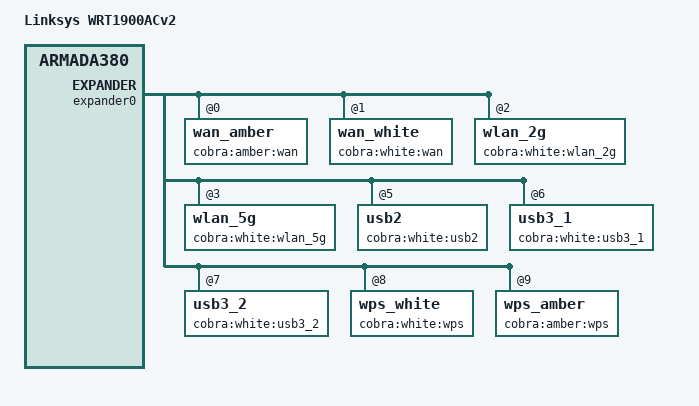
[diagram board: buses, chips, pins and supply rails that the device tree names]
// SPDX-License-Identifier: (GPL-2.0 OR MIT)
/*
 * Device Tree file for the Linksys WRT1900ACv2 (Cobra)
 *
 * Copyright (C) 2015 Imre Kaloz <kaloz@openwrt.org>
 */

/dts-v1/;
#include "armada-385-linksys.dtsi"

/ {
	model = "Linksys WRT1900ACv2";
	compatible = "linksys,wrt1900ac-v2", "linksys,cobra",
		     "linksys,armada385", "marvell,armada385",
		     "marvell,armada380";
};

&expander0 {
	wan_amber@0 {
		label = "cobra:amber:wan";
		reg = <0x0>;
	};

	wan_white@1 {
		label = "cobra:white:wan";
		reg = <0x1>;
	};

	wlan_2g@2 {
		label = "cobra:white:wlan_2g";
		reg = <0x2>;
	};

	wlan_5g@3 {
		label = "cobra:white:wlan_5g";
		reg = <0x3>;
	};

	usb2@5 {
		label = "cobra:white:usb2";
		reg = <0x5>;
	};

	usb3_1@6 {
		label = "cobra:white:usb3_1";
		reg = <0x6>;
	};

	usb3_2@7 {
		label = "cobra:white:usb3_2";
		reg = <0x7>;
	};

	wps_white@8 {
		label = "cobra:white:wps";
		reg = <0x8>;
	};

	wps_amber@9 {
		label = "cobra:amber:wps";
		reg = <0x9>;
	};
};

&gpio_leds {
	power {
		label = "cobra:white:power";
	};

	sata {
		label = "cobra:white:sata";
	};
};

&nand {
	/* 128MiB */
	partitions {
		compatible = "fixed-partitions";
		#address-cells = <1>;
		#size-cells = <1>;

				partition@0 {
					label = "u-boot";
					reg = <0x0000000 0x200000>;  /* 2MB */
					read-only;
				};

				partition@100000 {
					label = "u_env";
					reg = <0x200000 0x40000>;    /* 256KB */
				};

				partition@140000 {
					label = "s_env";
					reg = <0x240000 0x40000>;    /* 256KB */
				};

				partition@900000 {
					label = "devinfo";
					reg = <0x900000 0x100000>;   /* 1MB */
					read-only;
				};

				/* kernel1 overlaps with rootfs1 by design */
				partition@a00000 {
					label = "linux";
					reg = <0xa00000 0x2800000>;  /* 40MB */
				};

				partition@e00000 {
					label = "rootfs";
					reg = <0xe00000 0x2400000>;    /* 37MB */
				};

				/* kernel2 overlaps with rootfs2 by design */
				partition@3200000 {
					label = "linux2";
					reg = <0x3200000 0x2700000>; /* 40MB */
				};

				partition@3600000 {
					label = "rootfs2";
					reg = <0x3600000 0x2300000>; /* 34MB */
				};

				partition@5900000 {
					label = "nvram";
					reg = <0x5900000 0x40000>;
				};

				/*
				 * 38MB, last MB is for the BBT, not writable
				 */
				partition@5a00000 {
					label = "ddwrt";
					reg = <0x5a00000 0x2500000>;
				};


				/*
				 * Unused area between "s_env" and "devinfo".
				 * Moved here because otherwise the renumbered
				 * partitions would break the bootloader
				 * supplied bootargs
				 */
				partition@180000 {
					label = "unused_area";
					reg = <0x280000 0x680000>;   /* 6.5MB */
				};
	};
};

&pcie1 {
	mwlwifi {
		marvell,chainmask = <4 4>;
		marvell,powertable {
			AU =
				<36 0 0xd 0xd 0xd 0xd 0xd 0xd 0xd 0xd 0xe 0xe 0xe 0xe 0xe 0xe 0xe 0xe 0 0xf>,
				<40 0 0xd 0xd 0xd 0xd 0xd 0xd 0xd 0xd 0xe 0xe 0xe 0xe 0xe 0xe 0xe 0xe 0 0xf>,
				<44 0 0xd 0xd 0xd 0xd 0xd 0xd 0xd 0xd 0xe 0xe 0xe 0xe 0xe 0xe 0xe 0xe 0 0xf>,
				<48 0 0xd 0xd 0xd 0xd 0xd 0xd 0xd 0xd 0xe 0xe 0xe 0xe 0xe 0xe 0xe 0xe 0 0xf>,
				<52 0 0xd 0xd 0xd 0xd 0xd 0xd 0xd 0xd 0xe 0xe 0xe 0xe 0xe 0xe 0xe 0xe 0 0xf>,
				<56 0 0xd 0xd 0xd 0xd 0xd 0xd 0xd 0xd 0xe 0xe 0xe 0xe 0xe 0xe 0xe 0xe 0 0xf>,
				<60 0 0xd 0xd 0xd 0xd 0xd 0xd 0xd 0xd 0xe 0xe 0xe 0xe 0xe 0xe 0xe 0xe 0 0xf>,
				<64 0 0xd 0xd 0xd 0xd 0xd 0xd 0xd 0xd 0xe 0xe 0xe 0xe 0xe 0xe 0xe 0xe 0 0xf>,
				<100 0 0x14 0x14 0x14 0x14 0x14 0x14 0x14 0x14 0x14 0x14 0x14 0x14 0x14 0x14 0x14 0x14 0 0xf>,
				<104 0 0x14 0x14 0x14 0x14 0x14 0x14 0x14 0x14 0x14 0x14 0x14 0x14 0x14 0x14 0x14 0x14 0 0xf>,
				<108 0 0x14 0x14 0x14 0x14 0x14 0x14 0x14 0x14 0x14 0x14 0x14 0x14 0x14 0x14 0x14 0x14 0 0xf>,
				<112 0 0x14 0x14 0x14 0x14 0x14 0x14 0x14 0x14 0x14 0x14 0x14 0x14 0x14 0x14 0x14 0x14 0 0xf>,
				<116 0 0x14 0x14 0x14 0x14 0x14 0x14 0x14 0x14 0x14 0x14 0x14 0x14 0x14 0x14 0x14 0x14 0 0xf>,
				<120 0 0x14 0x14 0x14 0x14 0x14 0x14 0x14 0x14 0x14 0x14 0x14 0x14 0x14 0x14 0x14 0x14 0 0xf>,
				<124 0 0x14 0x14 0x14 0x14 0x14 0x14 0x14 0x14 0x14 0x14 0x14 0x14 0x14 0x14 0x14 0x14 0 0xf>,
				<128 0 0x14 0x14 0x14 0x14 0x14 0x14 0x14 0x14 0x14 0x14 0x14 0x14 0x14 0x14 0x14 0x14 0 0xf>,
				<132 0 0x14 0x14 0x14 0x14 0x14 0x14 0x14 0x14 0x14 0x14 0x14 0x14 0x14 0x14 0x14 0x14 0 0xf>,
				<136 0 0x14 0x14 0x14 0x14 0x14 0x14 0x14 0x14 0x14 0x14 0x14 0x14 0x14 0x14 0x14 0x14 0 0xf>,
				<140 0 0x14 0x14 0x14 0x14 0x14 0x14 0x14 0x14 0x14 0x14 0x14 0x14 0x14 0x14 0x14 0x14 0 0xf>,
				<149 0 0x19 0x19 0x19 0x17 0x19 0x19 0x16 0x15 0x19 0x19 0x16 0x15 0x19 0x19 0x16 0x15 0 0xf>,
				<153 0 0x19 0x19 0x19 0x17 0x19 0x19 0x16 0x15 0x19 0x19 0x16 0x15 0x19 0x19 0x16 0x15 0 0xf>,
				<157 0 0x19 0x19 0x19 0x17 0x19 0x19 0x16 0x15 0x19 0x19 0x16 0x15 0x19 0x19 0x16 0x15 0 0xf>,
				<161 0 0x19 0x19 0x19 0x17 0x19 0x19 0x16 0x15 0x19 0x19 0x16 0x15 0x19 0x19 0x16 0x15 0 0xf>,
				<165 0 0x19 0x19 0x19 0x17 0x19 0x19 0x16 0x15 0x19 0x19 0x16 0x15 0x19 0x19 0x16 0x15 0 0xf>;
			CA =
				<36 0 0x9 0x9 0x9 0x9 0x9 0x9 0x9 0x9 0x9 0x9 0x9 0x9 0x9 0x9 0x9 0x9 0 0xf>,
				<40 0 0x9 0x9 0x9 0x9 0x9 0x9 0x9 0x9 0x9 0x9 0x9 0x9 0x9 0x9 0x9 0x9 0 0xf>,
				<44 0 0x9 0x9 0x9 0x9 0x9 0x9 0x9 0x9 0x9 0x9 0x9 0x9 0x9 0x9 0x9 0x9 0 0xf>,
				<48 0 0x9 0x9 0x9 0x9 0x9 0x9 0x9 0x9 0x9 0x9 0x9 0x9 0x9 0x9 0x9 0x9 0 0xf>,
				<52 0 0x11 0x11 0x11 0x11 0x10 0x10 0x10 0x10 0x12 0x12 0x12 0x12 0x10 0x10 0x10 0x10 0 0xf>,
				<56 0 0x11 0x11 0x11 0x11 0x10 0x10 0x10 0x10 0x12 0x12 0x12 0x12 0x10 0x10 0x10 0x10 0 0xf>,
				<60 0 0x11 0x11 0x11 0x11 0x10 0x10 0x10 0x10 0x12 0x12 0x12 0x12 0x10 0x10 0x10 0x10 0 0xf>,
				<64 0 0x11 0x11 0x11 0x11 0x10 0x10 0x10 0x10 0x12 0x12 0x12 0x12 0x10 0x10 0x10 0x10 0 0xf>,
				<100 0 0x10 0x10 0x10 0x10 0x11 0x11 0x11 0x11 0x12 0x12 0x12 0x12 0x10 0x10 0x10 0x10 0 0xf>,
				<104 0 0x11 0x11 0x11 0x11 0x10 0x10 0x10 0x10 0x12 0x12 0x12 0x12 0x10 0x10 0x10 0x10 0 0xf>,
				<108 0 0x11 0x11 0x11 0x11 0x10 0x10 0x10 0x10 0x11 0x11 0x11 0x11 0x10 0x10 0x10 0x10 0 0xf>,
				<112 0 0x11 0x11 0x11 0x11 0x10 0x10 0x10 0x10 0x11 0x11 0x11 0x11 0x10 0x10 0x10 0x10 0 0xf>,
				<116 0 0x11 0x11 0x11 0x11 0x10 0x10 0x10 0x10 0x11 0x11 0x11 0x11 0x10 0x10 0x10 0x10 0 0xf>,
				<120 0 0x11 0x11 0x11 0x11 0x10 0x10 0x10 0x10 0x11 0x11 0x11 0x11 0x10 0x10 0x10 0x10 0 0xf>,
				<124 0 0x11 0x11 0x11 0x11 0x10 0x10 0x10 0x10 0x11 0x11 0x11 0x11 0x10 0x10 0x10 0x10 0 0xf>,
				<128 0 0x11 0x11 0x11 0x11 0x10 0x10 0x10 0x10 0x11 0x11 0x11 0x11 0x10 0x10 0x10 0x10 0 0xf>,
				<132 0 0x11 0x11 0x11 0x11 0x10 0x10 0x10 0x10 0x11 0x11 0x11 0x11 0x10 0x10 0x10 0x10 0 0xf>,
				<136 0 0x11 0x11 0x11 0x11 0x10 0x10 0x10 0x10 0x11 0x11 0x11 0x11 0x10 0x10 0x10 0x10 0 0xf>,
				<140 0 0x11 0x11 0x11 0x11 0x10 0x10 0x10 0x10 0x11 0x11 0x11 0x11 0x10 0x10 0x10 0x10 0 0xf>,
				<149 0 0x16 0x16 0x16 0x16 0x16 0x16 0x16 0x16 0x15 0x15 0x15 0x15 0x15 0x15 0x15 0x15 0 0xf>,
				<153 0 0x16 0x16 0x16 0x16 0x15 0x15 0x15 0x15 0x15 0x15 0x15 0x15 0x15 0x15 0x15 0x15 0 0xf>,
				<157 0 0x16 0x16 0x16 0x16 0x15 0x15 0x15 0x15 0x15 0x15 0x15 0x15 0x15 0x15 0x15 0x15 0 0xf>,
				<161 0 0x16 0x16 0x16 0x16 0x15 0x15 0x15 0x15 0x15 0x15 0x15 0x15 0x15 0x15 0x15 0x15 0 0xf>,
				<165 0 0x15 0x15 0x15 0x15 0x15 0x15 0x15 0x15 0x15 0x15 0x15 0x15 0x15 0x15 0x15 0x15 0 0xf>;
			CN =
				<36 0 0xd 0xd 0xd 0xd 0xd 0xd 0xd 0xd 0xe 0xe 0xe 0xe 0xe 0xe 0xe 0xe 0 0xf>,
				<40 0 0xd 0xd 0xd 0xd 0xd 0xd 0xd 0xd 0xe 0xe 0xe 0xe 0xe 0xe 0xe 0xe 0 0xf>,
				<44 0 0xd 0xd 0xd 0xd 0xd 0xd 0xd 0xd 0xe 0xe 0xe 0xe 0xe 0xe 0xe 0xe 0 0xf>,
				<48 0 0xd 0xd 0xd 0xd 0xd 0xd 0xd 0xd 0xe 0xe 0xe 0xe 0xe 0xe 0xe 0xe 0 0xf>,
				<52 0 0xd 0xd 0xd 0xd 0xd 0xd 0xd 0xd 0xe 0xe 0xe 0xe 0xe 0xe 0xe 0xe 0 0xf>,
				<56 0 0xd 0xd 0xd 0xd 0xd 0xd 0xd 0xd 0xe 0xe 0xe 0xe 0xe 0xe 0xe 0xe 0 0xf>,
				<60 0 0xd 0xd 0xd 0xd 0xd 0xd 0xd 0xd 0xe 0xe 0xe 0xe 0xe 0xe 0xe 0xe 0 0xf>,
				<64 0 0xd 0xd 0xd 0xd 0xd 0xd 0xd 0xd 0xe 0xe 0xe 0xe 0xe 0xe 0xe 0xe 0 0xf>,
				<100 0 0xd 0xd 0xd 0xd 0xd 0xd 0xd 0xd 0xe 0xe 0xe 0xe 0xe 0xe 0xe 0xe 0 0xf>,
				<104 0 0xd 0xd 0xd 0xd 0xd 0xd 0xd 0xd 0xe 0xe 0xe 0xe 0xe 0xe 0xe 0xe 0 0xf>,
				<108 0 0xd 0xd 0xd 0xd 0xd 0xd 0xd 0xd 0xe 0xe 0xe 0xe 0xe 0xe 0xe 0xe 0 0xf>,
				<112 0 0xd 0xd 0xd 0xd 0xd 0xd 0xd 0xd 0xe 0xe 0xe 0xe 0xe 0xe 0xe 0xe 0 0xf>,
				<116 0 0xd 0xd 0xd 0xd 0xd 0xd 0xd 0xd 0xe 0xe 0xe 0xe 0xe 0xe 0xe 0xe 0 0xf>,
				<120 0 0xd 0xd 0xd 0xd 0xd 0xd 0xd 0xd 0xe 0xe 0xe 0xe 0xe 0xe 0xe 0xe 0 0xf>,
				<124 0 0xd 0xd 0xd 0xd 0xd 0xd 0xd 0xd 0xe 0xe 0xe 0xe 0xe 0xe 0xe 0xe 0 0xf>,
				<128 0 0xd 0xd 0xd 0xd 0xd 0xd 0xd 0xd 0xe 0xe 0xe 0xe 0xe 0xe 0xe 0xe 0 0xf>,
				<132 0 0xd 0xd 0xd 0xd 0xd 0xd 0xd 0xd 0xe 0xe 0xe 0xe 0xe 0xe 0xe 0xe 0 0xf>,
				<136 0 0xd 0xd 0xd 0xd 0xd 0xd 0xd 0xd 0xe 0xe 0xe 0xe 0xe 0xe 0xe 0xe 0 0xf>,
				<140 0 0xd 0xd 0xd 0xd 0xd 0xd 0xd 0xd 0xe 0xe 0xe 0xe 0xe 0xe 0xe 0xe 0 0xf>,
				<149 0 0x14 0x14 0x14 0x14 0x13 0x13 0x13 0x13 0x11 0x11 0x11 0x11 0x10 0x10 0x10 0x10 0 0xf>,
				<153 0 0x16 0x16 0x16 0x16 0x15 0x15 0x15 0x15 0x14 0x14 0x14 0x14 0x10 0x10 0x10 0x10 0 0xf>,
				<157 0 0x16 0x16 0x16 0x16 0x15 0x15 0x15 0x15 0x14 0x14 0x14 0x14 0x10 0x10 0x10 0x10 0 0xf>,
				<161 0 0x16 0x16 0x16 0x16 0x15 0x15 0x15 0x15 0x14 0x14 0x14 0x14 0x10 0x10 0x10 0x10 0 0xf>,
				<165 0 0x13 0x13 0x13 0x13 0x13 0x13 0x13 0x13 0x14 0x14 0x14 0x14 0x10 0x10 0x10 0x10 0 0xf>;
			ETSI =
				<36 0 0xd 0xd 0xd 0xd 0xd 0xd 0xd 0xd 0xe 0xe 0xe 0xe 0xe 0xe 0xe 0xe 0 0xf>,
				<40 0 0xd 0xd 0xd 0xd 0xd 0xd 0xd 0xd 0xe 0xe 0xe 0xe 0xe 0xe 0xe 0xe 0 0xf>,
				<44 0 0xd 0xd 0xd 0xd 0xd 0xd 0xd 0xd 0xe 0xe 0xe 0xe 0xe 0xe 0xe 0xe 0 0xf>,
				<48 0 0xd 0xd 0xd 0xd 0xd 0xd 0xd 0xd 0xe 0xe 0xe 0xe 0xe 0xe 0xe 0xe 0 0xf>,
				<52 0 0xd 0xd 0xd 0xd 0xd 0xd 0xd 0xd 0xe 0xe 0xe 0xe 0xe 0xe 0xe 0xe 0 0xf>,
				<56 0 0xd 0xd 0xd 0xd 0xd 0xd 0xd 0xd 0xe 0xe 0xe 0xe 0xe 0xe 0xe 0xe 0 0xf>,
				<60 0 0xd 0xd 0xd 0xd 0xd 0xd 0xd 0xd 0xe 0xe 0xe 0xe 0xe 0xe 0xe 0xe 0 0xf>,
				<64 0 0xd 0xd 0xd 0xd 0xd 0xd 0xd 0xd 0xe 0xe 0xe 0xe 0xe 0xe 0xe 0xe 0 0xf>,
				<100 0 0xd 0xd 0xd 0xd 0xd 0xd 0xd 0xd 0xe 0xe 0xe 0xe 0xe 0xe 0xe 0xe 0 0xf>,
				<104 0 0xd 0xd 0xd 0xd 0xd 0xd 0xd 0xd 0xe 0xe 0xe 0xe 0xe 0xe 0xe 0xe 0 0xf>,
				<108 0 0xd 0xd 0xd 0xd 0xd 0xd 0xd 0xd 0xe 0xe 0xe 0xe 0xe 0xe 0xe 0xe 0 0xf>,
				<112 0 0xd 0xd 0xd 0xd 0xd 0xd 0xd 0xd 0xe 0xe 0xe 0xe 0xe 0xe 0xe 0xe 0 0xf>,
				<116 0 0xd 0xd 0xd 0xd 0xd 0xd 0xd 0xd 0xe 0xe 0xe 0xe 0xe 0xe 0xe 0xe 0 0xf>,
				<120 0 0xd 0xd 0xd 0xd 0xd 0xd 0xd 0xd 0xe 0xe 0xe 0xe 0xe 0xe 0xe 0xe 0 0xf>,
				<124 0 0xd 0xd 0xd 0xd 0xd 0xd 0xd 0xd 0xe 0xe 0xe 0xe 0xe 0xe 0xe 0xe 0 0xf>,
				<128 0 0xd 0xd 0xd 0xd 0xd 0xd 0xd 0xd 0xe 0xe 0xe 0xe 0xe 0xe 0xe 0xe 0 0xf>,
				<132 0 0xd 0xd 0xd 0xd 0xd 0xd 0xd 0xd 0xe 0xe 0xe 0xe 0xe 0xe 0xe 0xe 0 0xf>,
				<136 0 0xd 0xd 0xd 0xd 0xd 0xd 0xd 0xd 0xe 0xe 0xe 0xe 0xe 0xe 0xe 0xe 0 0xf>,
				<140 0 0xd 0xd 0xd 0xd 0xd 0xd 0xd 0xd 0xe 0xe 0xe 0xe 0xe 0xe 0xe 0xe 0 0xf>,
				<149 0 0xd 0xd 0xd 0xd 0xd 0xd 0xd 0xd 0xe 0xe 0xe 0xe 0xe 0xe 0xe 0xe 0 0xf>;
			FCC =
				<36 0 0x12 0x12 0x12 0x12 0x12 0x12 0x12 0x12 0x10 0x10 0x10 0x10 0xf 0xf 0xf 0xf 0 0xf>,
				<40 0 0x16 0x16 0x16 0x16 0x16 0x16 0x16 0x16 0x16 0x16 0x16 0x16 0xf 0xf 0xf 0xf 0 0xf>,
				<44 0 0x16 0x16 0x16 0x16 0x16 0x16 0x16 0x16 0x16 0x16 0x16 0x16 0xf 0xf 0xf 0xf 0 0xf>,
				<48 0 0x16 0x16 0x16 0x16 0x16 0x16 0x16 0x16 0x16 0x16 0x16 0x16 0xf 0xf 0xf 0xf 0 0xf>,
				<52 0 0x11 0x11 0x11 0x11 0x10 0x10 0x10 0x10 0x12 0x12 0x12 0x12 0x10 0x10 0x10 0x10 0 0xf>,
				<56 0 0x11 0x11 0x11 0x11 0x10 0x10 0x10 0x10 0x12 0x12 0x12 0x12 0x10 0x10 0x10 0x10 0 0xf>,
				<60 0 0x11 0x11 0x11 0x11 0x10 0x10 0x10 0x10 0x12 0x12 0x12 0x12 0x10 0x10 0x10 0x10 0 0xf>,
				<64 0 0x11 0x11 0x11 0x11 0x10 0x10 0x10 0x10 0x12 0x12 0x12 0x12 0x10 0x10 0x10 0x10 0 0xf>,
				<100 0 0x10 0x10 0x10 0x10 0x11 0x11 0x11 0x11 0x12 0x12 0x12 0x12 0x10 0x10 0x10 0x10 0 0xf>,
				<104 0 0x11 0x11 0x11 0x11 0x10 0x10 0x10 0x10 0x12 0x12 0x12 0x12 0x10 0x10 0x10 0x10 0 0xf>,
				<108 0 0x11 0x11 0x11 0x11 0x10 0x10 0x10 0x10 0x11 0x11 0x11 0x11 0x10 0x10 0x10 0x10 0 0xf>,
				<112 0 0x11 0x11 0x11 0x11 0x10 0x10 0x10 0x10 0x11 0x11 0x11 0x11 0x10 0x10 0x10 0x10 0 0xf>,
				<116 0 0x11 0x11 0x11 0x11 0x10 0x10 0x10 0x10 0x11 0x11 0x11 0x11 0x10 0x10 0x10 0x10 0 0xf>,
				<120 0 0x11 0x11 0x11 0x11 0x10 0x10 0x10 0x10 0x11 0x11 0x11 0x11 0x10 0x10 0x10 0x10 0 0xf>,
				<124 0 0x11 0x11 0x11 0x11 0x10 0x10 0x10 0x10 0x11 0x11 0x11 0x11 0x10 0x10 0x10 0x10 0 0xf>,
				<128 0 0x11 0x11 0x11 0x11 0x10 0x10 0x10 0x10 0x11 0x11 0x11 0x11 0x10 0x10 0x10 0x10 0 0xf>,
				<132 0 0x11 0x11 0x11 0x11 0x10 0x10 0x10 0x10 0x11 0x11 0x11 0x11 0x10 0x10 0x10 0x10 0 0xf>,
				<136 0 0x11 0x11 0x11 0x11 0x10 0x10 0x10 0x10 0x11 0x11 0x11 0x11 0x10 0x10 0x10 0x10 0 0xf>,
				<140 0 0x11 0x11 0x11 0x11 0x10 0x10 0x10 0x10 0x11 0x11 0x11 0x11 0x10 0x10 0x10 0x10 0 0xf>,
				<149 0 0x16 0x16 0x16 0x16 0x16 0x16 0x16 0x16 0x15 0x15 0x15 0x15 0x15 0x15 0x15 0x15 0 0xf>,
				<153 0 0x16 0x16 0x16 0x16 0x15 0x15 0x15 0x15 0x15 0x15 0x15 0x15 0x15 0x15 0x15 0x15 0 0xf>,
				<157 0 0x16 0x16 0x16 0x16 0x15 0x15 0x15 0x15 0x15 0x15 0x15 0x15 0x15 0x15 0x15 0x15 0 0xf>,
				<161 0 0x16 0x16 0x16 0x16 0x15 0x15 0x15 0x15 0x15 0x15 0x15 0x15 0x15 0x15 0x15 0x15 0 0xf>,
				<165 0 0x15 0x15 0x15 0x15 0x15 0x15 0x15 0x15 0x15 0x15 0x15 0x15 0x15 0x15 0x15 0x15 0 0xf>;
		};
	};
};

&pcie2 {
	mwlwifi {
		marvell,chainmask = <4 4>;
		marvell,powertable {
			AU =
				<1 0 0xa 0xa 0xa 0xa 0xa 0xa 0xa 0xa 0xa 0xa 0xa 0xa 0x0 0x0 0x0 0x0 0 0xf>,
				<2 0 0xa 0xa 0xa 0xa 0xa 0xa 0xa 0xa 0xa 0xa 0xa 0xa 0x0 0x0 0x0 0x0 0 0xf>,
				<3 0 0xa 0xa 0xa 0xa 0xa 0xa 0xa 0xa 0xa 0xa 0xa 0xa 0x0 0x0 0x0 0x0 0 0xf>,
				<4 0 0xa 0xa 0xa 0xa 0xa 0xa 0xa 0xa 0xa 0xa 0xa 0xa 0x0 0x0 0x0 0x0 0 0xf>,
				<5 0 0xa 0xa 0xa 0xa 0xa 0xa 0xa 0xa 0xa 0xa 0xa 0xa 0x0 0x0 0x0 0x0 0 0xf>,
				<6 0 0xa 0xa 0xa 0xa 0xa 0xa 0xa 0xa 0xa 0xa 0xa 0xa 0x0 0x0 0x0 0x0 0 0xf>,
				<7 0 0xa 0xa 0xa 0xa 0xa 0xa 0xa 0xa 0xa 0xa 0xa 0xa 0x0 0x0 0x0 0x0 0 0xf>,
				<8 0 0xa 0xa 0xa 0xa 0xa 0xa 0xa 0xa 0xa 0xa 0xa 0xa 0x0 0x0 0x0 0x0 0 0xf>,
				<9 0 0xa 0xa 0xa 0xa 0xa 0xa 0xa 0xa 0xa 0xa 0xa 0xa 0x0 0x0 0x0 0x0 0 0xf>,
				<10 0 0xa 0xa 0xa 0xa 0xa 0xa 0xa 0xa 0xa 0xa 0xa 0xa 0x0 0x0 0x0 0x0 0 0xf>,
				<11 0 0xa 0xa 0xa 0xa 0xa 0xa 0xa 0xa 0xa 0xa 0xa 0xa 0x0 0x0 0x0 0x0 0 0xf>;
			CA =
				<1 0 0x17 0x10 0x10 0x10 0xf 0xf 0xf 0xf 0xe 0xe 0xe 0xe 0x0 0x0 0x0 0x0 0 0xf>,
				<2 0 0x18 0x16 0x16 0x16 0x16 0x16 0x16 0x14 0x11 0x11 0x11 0x11 0x0 0x0 0x0 0x0 0 0xf>,
				<3 0 0x18 0x16 0x16 0x16 0x16 0x16 0x16 0x14 0x11 0x11 0x11 0x11 0x0 0x0 0x0 0x0 0 0xf>,
				<4 0 0x18 0x16 0x16 0x16 0x16 0x16 0x16 0x14 0x11 0x11 0x11 0x11 0x0 0x0 0x0 0x0 0 0xf>,
				<5 0 0x18 0x16 0x16 0x16 0x16 0x16 0x16 0x14 0x11 0x11 0x11 0x11 0x0 0x0 0x0 0x0 0 0xf>,
				<6 0 0x18 0x16 0x16 0x16 0x16 0x16 0x16 0x14 0x11 0x11 0x11 0x11 0x0 0x0 0x0 0x0 0 0xf>,
				<7 0 0x18 0x16 0x16 0x16 0x16 0x16 0x16 0x14 0x11 0x11 0x11 0x11 0x0 0x0 0x0 0x0 0 0xf>,
				<8 0 0x18 0x16 0x16 0x16 0x16 0x16 0x16 0x14 0x11 0x11 0x11 0x11 0x0 0x0 0x0 0x0 0 0xf>,
				<9 0 0x18 0x16 0x16 0x16 0x16 0x16 0x16 0x14 0x11 0x11 0x11 0x11 0x0 0x0 0x0 0x0 0 0xf>,
				<10 0 0x18 0x16 0x16 0x16 0x16 0x16 0x16 0x14 0x11 0x11 0x11 0x11 0x0 0x0 0x0 0x0 0 0xf>,
				<11 0 0x17 0x12 0x12 0x12 0x13 0x13 0x13 0x13 0xf 0xf 0xf 0xf 0x0 0x0 0x0 0x0 0 0xf>;
			CN =
				<1 0 0xa 0xa 0xa 0xa 0xa 0xa 0xa 0xa 0xa 0xa 0xa 0xa 0x0 0x0 0x0 0x0 0 0xf>,
				<2 0 0xa 0xa 0xa 0xa 0xa 0xa 0xa 0xa 0xa 0xa 0xa 0xa 0x0 0x0 0x0 0x0 0 0xf>,
				<3 0 0xa 0xa 0xa 0xa 0xa 0xa 0xa 0xa 0xa 0xa 0xa 0xa 0x0 0x0 0x0 0x0 0 0xf>,
				<4 0 0xa 0xa 0xa 0xa 0xa 0xa 0xa 0xa 0xa 0xa 0xa 0xa 0x0 0x0 0x0 0x0 0 0xf>,
				<5 0 0xa 0xa 0xa 0xa 0xa 0xa 0xa 0xa 0xa 0xa 0xa 0xa 0x0 0x0 0x0 0x0 0 0xf>,
				<6 0 0xa 0xa 0xa 0xa 0xa 0xa 0xa 0xa 0xa 0xa 0xa 0xa 0x0 0x0 0x0 0x0 0 0xf>,
				<7 0 0xa 0xa 0xa 0xa 0xa 0xa 0xa 0xa 0xa 0xa 0xa 0xa 0x0 0x0 0x0 0x0 0 0xf>,
				<8 0 0xa 0xa 0xa 0xa 0xa 0xa 0xa 0xa 0xa 0xa 0xa 0xa 0x0 0x0 0x0 0x0 0 0xf>,
				<9 0 0xa 0xa 0xa 0xa 0xa 0xa 0xa 0xa 0xa 0xa 0xa 0xa 0x0 0x0 0x0 0x0 0 0xf>,
				<10 0 0xa 0xa 0xa 0xa 0xa 0xa 0xa 0xa 0xa 0xa 0xa 0xa 0x0 0x0 0x0 0x0 0 0xf>,
				<11 0 0xa 0xa 0xa 0xa 0xa 0xa 0xa 0xa 0xa 0xa 0xa 0xa 0x0 0x0 0x0 0x0 0 0xf>,
				<12 0 0xa 0xa 0xa 0xa 0xa 0xa 0xa 0xa 0xa 0xa 0xa 0xa 0x0 0x0 0x0 0x0 0 0xf>,
				<13 0 0xa 0xa 0xa 0xa 0xa 0xa 0xa 0xa 0xa 0xa 0xa 0xa 0x0 0x0 0x0 0x0 0 0xf>,
				<14 0 0xa 0xa 0xa 0xa 0xa 0xa 0xa 0xa 0xa 0xa 0xa 0xa 0x0 0x0 0x0 0x0 0 0xf>;
			ETSI =
				<1 0 0xa 0xa 0xa 0xa 0xa 0xa 0xa 0xa 0xa 0xa 0xa 0xa 0x0 0x0 0x0 0x0 0 0xf>,
				<2 0 0xa 0xa 0xa 0xa 0xa 0xa 0xa 0xa 0xa 0xa 0xa 0xa 0x0 0x0 0x0 0x0 0 0xf>,
				<3 0 0xa 0xa 0xa 0xa 0xa 0xa 0xa 0xa 0xa 0xa 0xa 0xa 0x0 0x0 0x0 0x0 0 0xf>,
				<4 0 0xa 0xa 0xa 0xa 0xa 0xa 0xa 0xa 0xa 0xa 0xa 0xa 0x0 0x0 0x0 0x0 0 0xf>,
				<5 0 0xa 0xa 0xa 0xa 0xa 0xa 0xa 0xa 0xa 0xa 0xa 0xa 0x0 0x0 0x0 0x0 0 0xf>,
				<6 0 0xa 0xa 0xa 0xa 0xa 0xa 0xa 0xa 0xa 0xa 0xa 0xa 0x0 0x0 0x0 0x0 0 0xf>,
				<7 0 0xa 0xa 0xa 0xa 0xa 0xa 0xa 0xa 0xa 0xa 0xa 0xa 0x0 0x0 0x0 0x0 0 0xf>,
				<8 0 0xa 0xa 0xa 0xa 0xa 0xa 0xa 0xa 0xa 0xa 0xa 0xa 0x0 0x0 0x0 0x0 0 0xf>,
				<9 0 0xa 0xa 0xa 0xa 0xa 0xa 0xa 0xa 0xa 0xa 0xa 0xa 0x0 0x0 0x0 0x0 0 0xf>,
				<10 0 0xa 0xa 0xa 0xa 0xa 0xa 0xa 0xa 0xa 0xa 0xa 0xa 0x0 0x0 0x0 0x0 0 0xf>,
				<11 0 0xa 0xa 0xa 0xa 0xa 0xa 0xa 0xa 0xa 0xa 0xa 0xa 0x0 0x0 0x0 0x0 0 0xf>,
				<12 0 0xa 0xa 0xa 0xa 0xa 0xa 0xa 0xa 0xa 0xa 0xa 0xa 0x0 0x0 0x0 0x0 0 0xf>,
				<13 0 0xa 0xa 0xa 0xa 0xa 0xa 0xa 0xa 0xa 0xa 0xa 0xa 0x0 0x0 0x0 0x0 0 0xf>;
			FCC =
				<1 0 0x17 0x10 0x10 0x10 0xf 0xf 0xf 0xf 0xe 0xe 0xe 0xe 0x0 0x0 0x0 0x0 0 0xf>,
				<2 0 0x18 0x16 0x16 0x16 0x16 0x16 0x16 0x14 0x11 0x11 0x11 0x11 0x0 0x0 0x0 0x0 0 0xf>,
				<3 0 0x18 0x16 0x16 0x16 0x16 0x16 0x16 0x14 0x11 0x11 0x11 0x11 0x0 0x0 0x0 0x0 0 0xf>,
				<4 0 0x18 0x16 0x16 0x16 0x16 0x16 0x16 0x14 0x11 0x11 0x11 0x11 0x0 0x0 0x0 0x0 0 0xf>,
				<5 0 0x18 0x16 0x16 0x16 0x16 0x16 0x16 0x14 0x11 0x11 0x11 0x11 0x0 0x0 0x0 0x0 0 0xf>,
				<6 0 0x18 0x16 0x16 0x16 0x16 0x16 0x16 0x14 0x11 0x11 0x11 0x11 0x0 0x0 0x0 0x0 0 0xf>,
				<7 0 0x18 0x16 0x16 0x16 0x16 0x16 0x16 0x14 0x11 0x11 0x11 0x11 0x0 0x0 0x0 0x0 0 0xf>,
				<8 0 0x18 0x16 0x16 0x16 0x16 0x16 0x16 0x14 0x11 0x11 0x11 0x11 0x0 0x0 0x0 0x0 0 0xf>,
				<9 0 0x18 0x16 0x16 0x16 0x16 0x16 0x16 0x14 0x11 0x11 0x11 0x11 0x0 0x0 0x0 0x0 0 0xf>,
				<10 0 0x18 0x16 0x16 0x16 0x16 0x16 0x16 0x14 0x11 0x11 0x11 0x11 0x0 0x0 0x0 0x0 0 0xf>,
				<11 0 0x17 0x12 0x12 0x12 0x13 0x13 0x13 0x13 0xf 0xf 0xf 0xf 0x0 0x0 0x0 0x0 0 0xf>;
		};
	};
};
